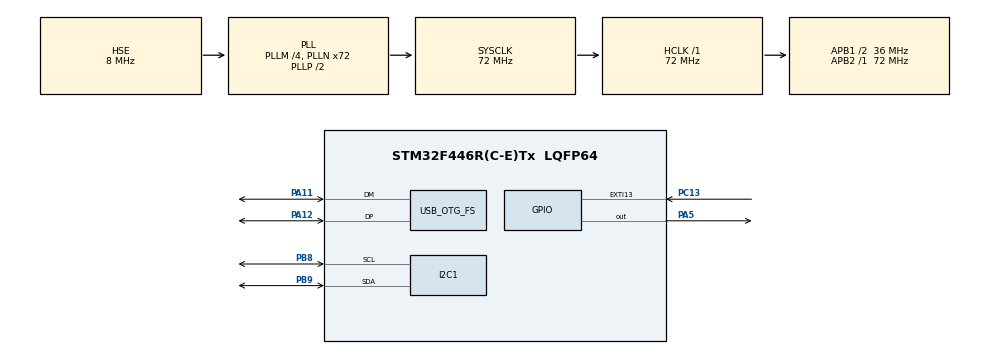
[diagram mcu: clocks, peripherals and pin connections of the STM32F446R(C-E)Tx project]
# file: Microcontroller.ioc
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FREERTOS.Queues01=servoCommandQueue,1,float,0,Dynamic,NULL,NULL
FREERTOS.Tasks01=servoTask,24,128,StartServoTask,Default,NULL,Dynamic,NULL,NULL
FREERTOS.configUSE_NEWLIB_REENTRANT=1
Mcu.Family=STM32F4
Mcu.Name=STM32F446R(C-E)Tx
Mcu.Package=LQFP64
NUCLEO-F446RE.BUTTON=1
NUCLEO-F446RE.Bsp_Common_DEMO=true
NUCLEO-F446RE.LD1=true
NVIC.EXTI15_10_IRQn=true\:5\:0\:false\:false\:true\:true\:false\:true\:true
NVIC.OTG_FS_IRQn=true\:5\:0\:false\:false\:true\:true\:false\:true\:true
NVIC.PriorityGroup=NVIC_PRIORITYGROUP_4
NVIC.TIM7_IRQn=true\:0\:0\:true\:false\:true\:false\:false\:true\:true
NVIC.TimeBase=TIM7_IRQn
NVIC.TimeBaseIP=TIM7
PA11.Mode=Device_Only
PA11.Signal=USB_OTG_FS_DM
PA12.Mode=Device_Only
PA12.Signal=USB_OTG_FS_DP
PA13.GPIO_Label=TMS
PA13.Signal=SYS_JTMS-SWDIO
PA14.GPIO_Label=TCK
PA14.Signal=SYS_JTCK-SWCLK
PA2.GPIO_Label=USART_TX
PA2.Signal=USART2_TX
PA3.GPIO_Label=USART_RX
PA3.Signal=USART2_RX
PA5.Signal=GPIO_Output
PB8.Mode=I2C
PB8.Signal=I2C1_SCL
PB9.Mode=I2C
PB9.Signal=I2C1_SDA
PC13.Signal=GPXTI13
PC14-OSC32_IN.Signal=RCC_OSC32_IN
PC15-OSC32_OUT.Signal=RCC_OSC32_OUT
PH0-OSC_IN.Mode=HSE-External-Clock-Source
PH0-OSC_IN.Signal=RCC_OSC_IN
PH1-OSC_OUT.Mode=HSE-External-Clock-Source
PH1-OSC_OUT.Signal=RCC_OSC_OUT
ProjectManager.HeapSize=0x200
ProjectManager.StackSize=0x400
ProjectManager.TargetToolchain=STM32CubeIDE
RCC.AHBFreq_Value=72000000
RCC.APB1CLKDivider=RCC_HCLK_DIV2
RCC.APB1Freq_Value=36000000
RCC.APB1TimFreq_Value=72000000
RCC.APB2Freq_Value=72000000
RCC.APB2TimFreq_Value=72000000
RCC.CortexFreq_Value=72000000
RCC.FLatency-AdvancedSettings=FLASH_LATENCY_2
RCC.HCLKFreq_Value=72000000
RCC.HSE_VALUE=8000000
RCC.HSI_VALUE=16000000
RCC.LSE_VALUE=32768
RCC.PLLM=4
RCC.PLLN=72
RCC.PLLQ=3
RCC.PLLSourceVirtual=RCC_PLLSOURCE_HSE
RCC.SYSCLKFreq_VALUE=72000000
RCC.SYSCLKSource=RCC_SYSCLKSOURCE_PLLCLK
RCC.USBFreq_Value=48000000
RCC.VCOOutputFreq_Value=144000000
USB_DEVICE.CLASS_NAME_FS=CDC
USB_DEVICE.VirtualMode-CDC_FS=Cdc
USB_DEVICE.VirtualModeFS=Cdc_FS
USB_OTG_FS.VirtualMode=Device_Only
VP_FREERTOS_VS_CMSIS_V2.Mode=CMSIS_V2
VP_NUCLEO-F446RE_VS_BSP_COMMON.Mode=COMMON
VP_SYS_VS_tim7.Mode=TIM7
VP_USB_DEVICE_VS_USB_DEVICE_CDC_FS.Mode=CDC_FS
board=NUCLEO-F446RE

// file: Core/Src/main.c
/* USER CODE BEGIN Header */
/**
  ******************************************************************************
  * @file           : main.c
  * @brief          : Main program body
  ******************************************************************************
  * @attention
  *
  * Copyright (c) 2026 STMicroelectronics.
  * All rights reserved.
  *
  * This software is licensed under terms that can be found in the LICENSE file
  * in the root directory of this software component.
  * If no LICENSE file comes with this software, it is provided AS-IS.
  *
  ******************************************************************************
  */
/* USER CODE END Header */
#include "main.h"
#include "cmsis_os.h"
#include "usb_device.h"

/* USER CODE BEGIN Includes */
// #include "alt_main.h"
#include "rtos.h"

/* USER CODE END Includes */

/* Button state */
#define BUTTON_RELEASED                    0U
#define BUTTON_PRESSED                     1U

__IO uint32_t BspButtonState = BUTTON_RELEASED;
I2C_HandleTypeDef hi2c1;

/* Definitions for servoTask */
osThreadId_t servoTaskHandle;
const osThreadAttr_t servoTask_attributes = {
  .name = "servoTask",
  .stack_size = 128 * 4,
  .priority = (osPriority_t) osPriorityNormal,
};
/* Definitions for servoCommandQueue */
osMessageQueueId_t servoCommandQueueHandle;
const osMessageQueueAttr_t servoCommandQueue_attributes = {
  .name = "servoCommandQueue"
};

void SystemClock_Config(void);
static void MX_GPIO_Init(void);
static void MX_I2C1_Init(void);
void StartServoTask(void *argument);

int main(void)
{

  /* MCU Configuration--------------------------------------------------------*/

  /* Reset of all peripherals, Initializes the Flash interface and the Systick. */
  HAL_Init();

  /* Configure the system clock */
  SystemClock_Config();

  /* Initialize all configured peripherals */
  MX_GPIO_Init();
  MX_I2C1_Init();

  /* Init scheduler */
  osKernelInitialize();

  /* Create the queue(s) */
  /* creation of servoCommandQueue */
  servoCommandQueueHandle = osMessageQueueNew (1, sizeof(float), &servoCommandQueue_attributes);

  /* Create the thread(s) */
  /* creation of servoTask */
  servoTaskHandle = osThreadNew(StartServoTask, NULL, &servoTask_attributes);

  /* Initialize leds */
  BSP_LED_Init(LED2);

  /* Initialize USER push-button, will be used to trigger an interrupt each time it's pressed.*/
  BSP_PB_Init(BUTTON_USER, BUTTON_MODE_EXTI);

  /* USER CODE BEGIN BSP */

  /* -- Sample board code to switch on leds ---- */
  BSP_LED_On(LED2);

  /* USER CODE END BSP */

  /* Start scheduler */
  osKernelStart();

  /* We should never get here as control is now taken by the scheduler */

  /* Infinite loop */
  /* USER CODE BEGIN WHILE */

  // Params params = {
	//   .timerInitList = {
	// 		.hip = { &htim2, TIM_CHANNEL_2 },   // PB3
	// 		.shoulder = { &htim3, TIM_CHANNEL_1 },    // PB4
	// 		.elbow = { &htim2, TIM_CHANNEL_3 },   // PB10
	// 		.wrist = { &htim8, TIM_CHANNEL_2 },   // PC7
	// 		.wristRot = { &htim4, TIM_CHANNEL_1 },    // PB6
	// 		.claw = { &htim3, TIM_CHANNEL_2 }   // PA7
	//   },
	//   .i2cInit = { &hi2c1 }
  // };

  // alt_main(&params, &BspButtonState);

  while (1)
  {

    /* -- Sample board code for User push-button in interrupt mode ---- */
   if (BspButtonState == BUTTON_PRESSED)
   {
     /* Update button state */
     BspButtonState = BUTTON_RELEASED;
     /* -- Sample board code to toggle leds ---- */
     BSP_LED_Toggle(LED2);

     /* ..... Perform your action ..... */
   }

    /* USER CODE END WHILE */

  }
}

void SystemClock_Config(void)
{
  RCC_OscInitTypeDef RCC_OscInitStruct = {0};
  RCC_ClkInitTypeDef RCC_ClkInitStruct = {0};

  /** Configure the main internal regulator output voltage
  */
  __HAL_RCC_PWR_CLK_ENABLE();
  __HAL_PWR_VOLTAGESCALING_CONFIG(PWR_REGULATOR_VOLTAGE_SCALE3);

  /** Initializes the RCC Oscillators according to the specified parameters
  * in the RCC_OscInitTypeDef structure.
  */
  RCC_OscInitStruct.OscillatorType = RCC_OSCILLATORTYPE_HSE;
  RCC_OscInitStruct.HSEState = RCC_HSE_BYPASS;
  RCC_OscInitStruct.PLL.PLLState = RCC_PLL_ON;
  RCC_OscInitStruct.PLL.PLLSource = RCC_PLLSOURCE_HSE;
  RCC_OscInitStruct.PLL.PLLM = 4;
  RCC_OscInitStruct.PLL.PLLN = 72;
  RCC_OscInitStruct.PLL.PLLP = RCC_PLLP_DIV2;
  RCC_OscInitStruct.PLL.PLLQ = 3;
  RCC_OscInitStruct.PLL.PLLR = 2;
  if (HAL_RCC_OscConfig(&RCC_OscInitStruct) != HAL_OK)
  {
    Error_Handler();
  }

  /** Initializes the CPU, AHB and APB buses clocks
  */
  RCC_ClkInitStruct.ClockType = RCC_CLOCKTYPE_HCLK|RCC_CLOCKTYPE_SYSCLK
                              |RCC_CLOCKTYPE_PCLK1|RCC_CLOCKTYPE_PCLK2;
  RCC_ClkInitStruct.SYSCLKSource = RCC_SYSCLKSOURCE_PLLCLK;
  RCC_ClkInitStruct.AHBCLKDivider = RCC_SYSCLK_DIV1;
  RCC_ClkInitStruct.APB1CLKDivider = RCC_HCLK_DIV2;
  RCC_ClkInitStruct.APB2CLKDivider = RCC_HCLK_DIV1;

  if (HAL_RCC_ClockConfig(&RCC_ClkInitStruct, FLASH_LATENCY_2) != HAL_OK)
  {
    Error_Handler();
  }
}

static void MX_I2C1_Init(void)
{

  hi2c1.Instance = I2C1;
  hi2c1.Init.ClockSpeed = 100000;
  hi2c1.Init.DutyCycle = I2C_DUTYCYCLE_2;
  hi2c1.Init.OwnAddress1 = 0;
  hi2c1.Init.AddressingMode = I2C_ADDRESSINGMODE_7BIT;
  hi2c1.Init.DualAddressMode = I2C_DUALADDRESS_DISABLE;
  hi2c1.Init.OwnAddress2 = 0;
  hi2c1.Init.GeneralCallMode = I2C_GENERALCALL_DISABLE;
  hi2c1.Init.NoStretchMode = I2C_NOSTRETCH_DISABLE;
  if (HAL_I2C_Init(&hi2c1) != HAL_OK)
  {
    Error_Handler();
  }

}

static void MX_GPIO_Init(void)
{
  GPIO_InitTypeDef GPIO_InitStruct = {0};

  /* GPIO Ports Clock Enable */
  __HAL_RCC_GPIOC_CLK_ENABLE();
  __HAL_RCC_GPIOH_CLK_ENABLE();
  __HAL_RCC_GPIOA_CLK_ENABLE();
  __HAL_RCC_GPIOB_CLK_ENABLE();

  /*Configure GPIO pins : USART_TX_Pin USART_RX_Pin */
  GPIO_InitStruct.Pin = USART_TX_Pin|USART_RX_Pin;
  GPIO_InitStruct.Mode = GPIO_MODE_AF_PP;
  GPIO_InitStruct.Pull = GPIO_NOPULL;
  GPIO_InitStruct.Speed = GPIO_SPEED_FREQ_VERY_HIGH;
  GPIO_InitStruct.Alternate = GPIO_AF7_USART2;
  HAL_GPIO_Init(GPIOA, &GPIO_InitStruct);

}

/* USER CODE BEGIN Header_StartServoTask */
/**
  * @brief  Function implementing the servoTask thread.
  * @param  argument: i2c handle: { .i2c = hi2c1 }
  * @retval None
  */
/* USER CODE END Header_StartServoTask */
void StartServoTask(void *argument)
{
  /* init code for USB_DEVICE */
  MX_USB_DEVICE_Init();
  /* USER CODE BEGIN 5 */
  vServoTask(argument);
  /* USER CODE END 5 */
}

void HAL_TIM_PeriodElapsedCallback(TIM_HandleTypeDef *htim)
{
  if (htim->Instance == TIM7)
  {
    HAL_IncTick();
  }
}

/**
  * @brief EXTI line detection callbacks
  * @param GPIO_Pin: Specifies the pins connected EXTI line
  * @retval None
  */
void HAL_GPIO_EXTI_Callback(uint16_t GPIO_Pin)
{
  if(GPIO_Pin==USER_BUTTON_PIN)
  {
    BspButtonState = BUTTON_PRESSED;
  }
}

void Error_Handler(void)
{
  __disable_irq();
  while (1)
  {
  }
}
